# cslr_memprot_L1P register map
Vendor: Texas Instruments
Peripheral module from a debugger description file.
Registers are 32-bit, access per field, reset 0x0 unless marked. A register's access mark holds for its fields unless they carry their own. Offsets are as the file gives them; lines under a group give offsets from that group; [hi:lo] are bit positions; {n}, {i} and the like mark numbered series; 'fields as' and 'values as' point back to an identical list; <NAME> marks a mode.

## MEMPROTL1P — Memory Protection for L1P
0x00 MPFAR rw — L1P Memory Protection Fault Address Reg
  [31:0] ADDR — L1P Fault Address
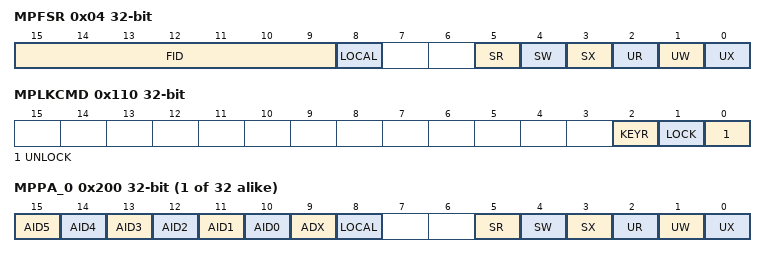
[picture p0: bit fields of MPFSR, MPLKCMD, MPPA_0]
0x04 MPFSR ro — L1P Memory Protection Fault Status Reg
  [15:9] FID — Bit 6:0 of faulting requestor. If ID is narrower than 7 bits, the remaining bits return 0. If ID is wider than 7 bits, the additional bits get truncated. FID = 0 if LOCAL = 1.
  [8] LOCAL — 0 - Normal operation. 1- Access was a "LOCAL" access.
  [5] SR — Superviser read access type
  [4] SW — Superviser write access type
  [3] SX — Superviser execute access type
  [2] UR — User read access type
  [1] UW — User write access type
  [0] UX — User execute access type
0x08 MPFCR — L1P Memory Fault Clear Register
  [0] MPFCLR wo — Set to clear fault
    1=CLEAR (Clears Fault)
{0x100+4i} MPLK{i} access not given (i=0..3) — L1P Memory Protection Lock Key bits {32i+31}:{32i}
  [31:0] Reserved — (access N)
0x110 MPLKCMD — L1P Memory Protection Lock Key Command Register
  [2] KEYR wo — Interface to initiate a lock/unlock sequence
    1=YES (Indicates the lock\unlock sequence and resets any state associated with the lock\unlock sequence); 0=NO (No effect)
  [1] LOCK wo — Interface to complete a lock sequence
    1=YES (Locks the lock provided that the software executed the sequence correctly); 0=NO (No effect)
  [0] UNLOCK wo — Interface to complete a unlock sequence
    1=YES (Unlocks the lock provided that the software executed the sequence correctly); 0=NO (No effect)
0x114 MPLKSTAT ro — L1P Memory Protection Lock Key Status Register
  [0] LK — Lock Status
    1=YES (Lock is engaged); 0=NO (Lock is not engaged)
{0x200+4i} MPPA_{i} (i=0..31) — L1P Memory Protection Page Attribute Register
  [15] AID5 rw — Controls access from ID = 5.
    0=NO (Access denied.); 1=YES (Access granted.)
  [14] AID4 rw — Controls access from ID = 4.
    0=NO (Access denied.); 1=YES (Access granted.)
  [13] AID3 rw — Controls access from ID = 3.
    0=NO (Access denied.); 1=YES (Access granted.)
  [12] AID2 rw — Controls access from ID =2.
    0=NO (Access denied.); 1=YES (Access granted.)
  [11] AID1 rw — Controls access from ID = 1.
    0=NO (Access denied.); 1=YES (Access granted.)
  [10] AID0 rw — Controls access from ID = 0.
    0=NO (Access denied.); 1=YES (Access granted.)
  [9] ADX rw — Controls ID >=6.
    0=NO (Access denied.); 1=YES (Access granted.)
  [8] LOCAL rw — Controls access from CPU to local memories (L1/L2).
    0=NO (Access denied.); 1=YES (Access granted.)
  [5] SR rw — Supervisor read access type.
    0=NO (Normal operation); 1=YES (Indicates a Supervisor read request.)
  [4] SW rw — Supervisor write access type.
    0=NO (Normal operation); 1=YES (Indicates a Supervisor write request.)
  [3] SX rw — Supervisor execute access type.
    0=NO (Normal operation); 1=YES (Indicates a Supervisor execute request.)
  [2] UR rw — User read access type.
    0=NO (Normal operation); 1=YES (Indicates a user read request.)
  [1] UW rw — User write access type.
    0=NO (Normal operation); 1=YES (Indicates a user write request.)
  [0] UX rw — User execute access type.
    0=NO (Normal operation); 1=YES (Indicates a user execute request.)
